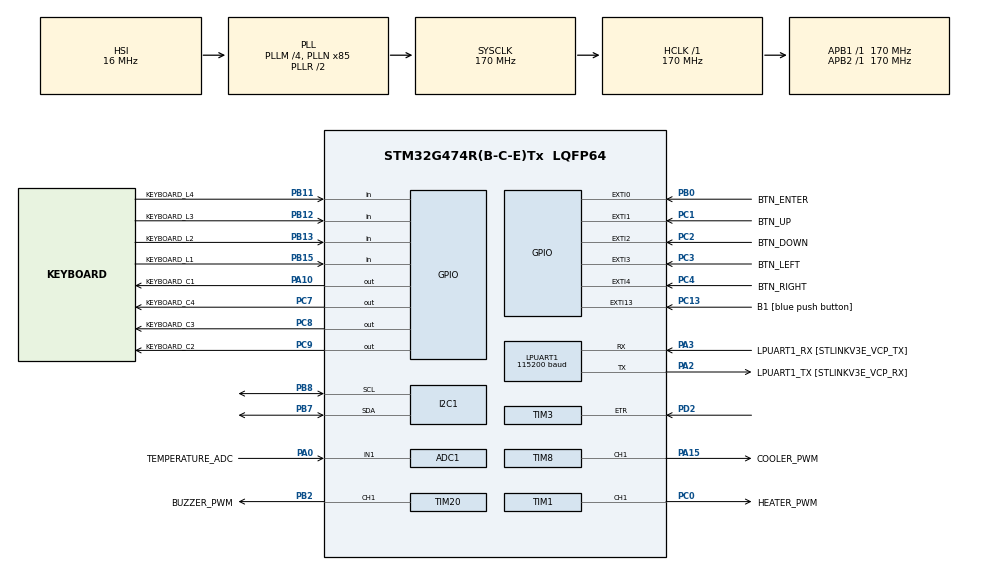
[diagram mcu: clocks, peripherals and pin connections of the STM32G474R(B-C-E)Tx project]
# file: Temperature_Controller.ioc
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ADC1.Channel-0\#ChannelRegularConversion=ADC_CHANNEL_1
ADC1.ClockPrescaler=ADC_CLOCK_ASYNC_DIV64
ADC1.ContinuousConvMode=ENABLE
ADC1.DMAContinuousRequests=ENABLE
ADC1.NbrOfConversionFlag=1
ADC1.OffsetNumber-0\#ChannelRegularConversion=ADC_OFFSET_NONE
ADC1.OversamplingMode=ENABLE
ADC1.Rank-0\#ChannelRegularConversion=1
ADC1.Ratio=ADC_OVERSAMPLING_RATIO_16
ADC1.RightBitShift=ADC_RIGHTBITSHIFT_4
ADC1.SamplingTime-0\#ChannelRegularConversion=ADC_SAMPLETIME_2CYCLES_5
ADC1.master=1
Dma.ADC1.0.Direction=DMA_PERIPH_TO_MEMORY
Dma.ADC1.0.EventEnable=DISABLE
Dma.ADC1.0.Instance=DMA1_Channel1
Dma.ADC1.0.MemDataAlignment=DMA_MDATAALIGN_HALFWORD
Dma.ADC1.0.MemInc=DMA_MINC_ENABLE
Dma.ADC1.0.Mode=DMA_CIRCULAR
Dma.ADC1.0.PeriphDataAlignment=DMA_PDATAALIGN_HALFWORD
Dma.ADC1.0.PeriphInc=DMA_PINC_DISABLE
Dma.ADC1.0.Polarity=HAL_DMAMUX_REQ_GEN_RISING
Dma.ADC1.0.Priority=DMA_PRIORITY_LOW
Dma.ADC1.0.RequestNumber=1
Dma.ADC1.0.SignalID=NONE
Dma.ADC1.0.SyncEnable=DISABLE
Dma.ADC1.0.SyncPolarity=HAL_DMAMUX_SYNC_NO_EVENT
Dma.ADC1.0.SyncRequestNumber=1
Dma.ADC1.0.SyncSignalID=NONE
Dma.Request0=ADC1
I2C1.Timing=0x30A0A7FB
LPUART1.BaudRate=115200
LPUART1.WordLength=UART_WORDLENGTH_8B
Mcu.Family=STM32G4
Mcu.Name=STM32G474R(B-C-E)Tx
Mcu.Package=LQFP64
NVIC.DMA1_Channel1_IRQn=true\:0\:0\:false\:false\:true\:false\:true\:true
NVIC.EXTI0_IRQn=true\:0\:0\:false\:false\:true\:true\:true\:true
NVIC.EXTI15_10_IRQn=true\:0\:0\:false\:false\:true\:true\:true\:true
NVIC.EXTI1_IRQn=true\:0\:0\:false\:false\:true\:true\:true\:true
NVIC.EXTI2_IRQn=true\:0\:0\:false\:false\:true\:true\:true\:true
NVIC.EXTI3_IRQn=true\:0\:0\:false\:false\:true\:true\:true\:true
NVIC.EXTI4_IRQn=true\:0\:0\:false\:false\:true\:true\:true\:true
NVIC.I2C1_EV_IRQn=true\:3\:0\:true\:false\:true\:true\:true\:true
NVIC.LPUART1_IRQn=true\:3\:0\:true\:false\:true\:true\:true\:true
NVIC.PriorityGroup=NVIC_PRIORITYGROUP_4
NVIC.TIM1_TRG_COM_TIM17_IRQn=true\:0\:0\:false\:false\:true\:true\:true\:true
NVIC.TIM1_UP_TIM16_IRQn=true\:3\:0\:true\:false\:true\:true\:true\:true
NVIC.TIM2_IRQn=true\:0\:0\:false\:false\:true\:true\:true\:true
NVIC.TIM4_IRQn=true\:1\:0\:true\:false\:true\:true\:true\:true
NVIC.TIM5_IRQn=true\:5\:0\:true\:false\:true\:true\:true\:true
NVIC.TIM6_DAC_IRQn=true\:3\:0\:true\:false\:true\:true\:true\:true
NVIC.TIM7_DAC_IRQn=true\:3\:0\:true\:false\:true\:true\:true\:true
PA0.GPIO_Label=TEMPERATURE_ADC
PA0.Mode=IN1-Single-Ended
PA0.Signal=ADC1_IN1
PA10.GPIO_Label=KEYBOARD_C1
PA10.Signal=GPIO_Output
PA13.GPIO_Label=T_SWDIO
PA13.Mode=Serial_Wire
PA13.Signal=SYS_JTMS-SWDIO
PA14.GPIO_Label=T_SWCLK
PA14.Mode=Serial_Wire
PA14.Signal=SYS_JTCK-SWCLK
PA15.GPIO_Label=COOLER_PWM
PA15.Signal=S_TIM8_CH1
PA2.GPIO_Label=LPUART1_TX [STLINKV3E_VCP_RX]
PA2.Mode=Asynchronous
PA2.Signal=LPUART1_TX
PA3.GPIO_Label=LPUART1_RX [STLINKV3E_VCP_TX]
PA3.Mode=Asynchronous
PA3.Signal=LPUART1_RX
PB0.GPIO_Label=BTN_ENTER
PB0.Signal=GPXTI0
PB11.GPIO_Label=KEYBOARD_L4
PB11.Signal=GPIO_Input
PB12.GPIO_Label=KEYBOARD_L3
PB12.Signal=GPIO_Input
PB13.GPIO_Label=KEYBOARD_L2
PB13.Signal=GPIO_Input
PB15.GPIO_Label=KEYBOARD_L1
PB15.Signal=GPIO_Input
PB2.GPIO_Label=BUZZER_PWM
PB2.Signal=S_TIM20_CH1
PB3.GPIO_Label=T_SWO
PB3.Signal=SYS_JTDO-SWO
PB7.Mode=I2C
PB7.Signal=I2C1_SDA
PB8-BOOT0.Mode=I2C
PB8-BOOT0.Signal=I2C1_SCL
PC0.GPIO_Label=HEATER_PWM
PC0.Signal=S_TIM1_CH1
PC1.GPIO_Label=BTN_UP
PC1.GPIO_ModeDefaultEXTI=GPIO_MODE_IT_RISING_FALLING
PC1.Signal=GPXTI1
PC13.GPIO_Label=B1 [blue push button]
PC13.Signal=GPXTI13
PC14-OSC32_IN.Mode=LSE-External-Oscillator
PC14-OSC32_IN.Signal=RCC_OSC32_IN
PC15-OSC32_OUT.Mode=LSE-External-Oscillator
PC15-OSC32_OUT.Signal=RCC_OSC32_OUT
PC2.GPIO_Label=BTN_DOWN
PC2.GPIO_ModeDefaultEXTI=GPIO_MODE_IT_RISING_FALLING
PC2.Signal=GPXTI2
PC3.GPIO_Label=BTN_LEFT
PC3.GPIO_ModeDefaultEXTI=GPIO_MODE_IT_RISING_FALLING
PC3.Signal=GPXTI3
PC4.GPIO_Label=BTN_RIGHT
PC4.GPIO_ModeDefaultEXTI=GPIO_MODE_IT_RISING_FALLING
PC4.Signal=GPXTI4
PC7.GPIO_Label=KEYBOARD_C4
PC7.Signal=GPIO_Output
PC8.GPIO_Label=KEYBOARD_C3
PC8.Signal=GPIO_Output
PC9.GPIO_Label=KEYBOARD_C2
PC9.Signal=GPIO_Output
PD2.Signal=S_TIM3_ETR
PF0-OSC_IN.Mode=HSE-External-Oscillator
PF0-OSC_IN.Signal=RCC_OSC_IN
PF1-OSC_OUT.Mode=HSE-External-Oscillator
PF1-OSC_OUT.Signal=RCC_OSC_OUT
ProjectManager.HeapSize=0x200
ProjectManager.StackSize=0x400
ProjectManager.TargetToolchain=STM32CubeIDE
RCC.ADC12Freq_Value=170000000
RCC.ADC345Freq_Value=170000000
RCC.AHBFreq_Value=170000000
RCC.APB1Freq_Value=170000000
RCC.APB1TimFreq_Value=170000000
RCC.APB2Freq_Value=170000000
RCC.APB2TimFreq_Value=170000000
RCC.CortexFreq_Value=170000000
RCC.EXTERNAL_CLOCK_VALUE=12288000
RCC.HCLKFreq_Value=170000000
RCC.HSE_VALUE=24000000
RCC.HSI48_VALUE=48000000
RCC.HSI_VALUE=16000000
RCC.PLLM=RCC_PLLM_DIV4
RCC.PLLN=85
RCC.RTCClockSelection=RCC_RTCCLKSOURCE_LSE
RCC.SYSCLKFreq_VALUE=170000000
RCC.SYSCLKSource=RCC_SYSCLKSOURCE_PLLCLK
RCC.USBFreq_Value=170000000
RCC.VCOOutputFreq_Value=340000000
SH.S_TIM1_CH1.0=TIM1_CH1,PWM Generation1 CH1
SH.S_TIM20_CH1.0=TIM20_CH1,PWM Generation1 CH1
SH.S_TIM3_ETR.0=TIM3_ETR,ClockSourceETR_Mode2
SH.S_TIM8_CH1.0=TIM8_CH1,PWM Generation1 CH1
TIM1.Channel-PWM\ Generation1\ CH1=TIM_CHANNEL_1
TIM1.PeriodNoDither=10000-1
TIM1.Prescaler=17-1
TIM16.PeriodNoDither=10000-1
TIM16.Prescaler=170-1
TIM2.PeriodNoDither=500000
TIM2.Prescaler=170-1
TIM20.Channel-PWM\ Generation1\ CH1=TIM_CHANNEL_1
TIM20.PeriodNoDither=10000-1
TIM20.Prescaler=17-1
TIM4.PeriodNoDither=10000
TIM4.Prescaler=17-1
TIM5.PeriodNoDither=1000000
TIM5.Prescaler=170-1
TIM6.PeriodNoDither=10000-1
TIM6.Prescaler=170-1
TIM7.PeriodNoDither=10000-1
TIM7.Prescaler=170-1
TIM8.Channel-PWM\ Generation1\ CH1=TIM_CHANNEL_1
TIM8.PeriodNoDither=10000
TIM8.Prescaler=17-1
VP_SYS_VS_DBSignals.Mode=DisableDeadBatterySignals
VP_TIM16_VS_ClockSourceINT.Mode=Enable_Timer
VP_TIM1_VS_ClockSourceINT.Mode=Internal
VP_TIM20_VS_ClockSourceINT.Mode=Internal
VP_TIM2_VS_ClockSourceINT.Mode=Internal
VP_TIM4_VS_ClockSourceINT.Mode=Internal
VP_TIM5_VS_ClockSourceINT.Mode=Internal
VP_TIM6_VS_ClockSourceINT.Mode=Enable_Timer
VP_TIM7_VS_ClockSourceINT.Mode=Enable_Timer
VP_TIM8_VS_ClockSourceINT.Mode=Internal
board=NUCLEO-G474RE

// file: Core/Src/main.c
/* USER CODE BEGIN Header */
/**
 ******************************************************************************
 * @file           : main.c
 * @brief          : Main program body
 ******************************************************************************
 * @attention
 *
 * Copyright (c) 2024 STMicroelectronics.
 * All rights reserved.
 *
 * This software is licensed under terms that can be found in the LICENSE file
 * in the root directory of this software component.
 * If no LICENSE file comes with this software, it is provided AS-IS.
 *
 ******************************************************************************
 */
/* USER CODE END Header */
#include "main.h"
#include "adc.h"
#include "dma.h"
#include "i2c.h"
#include "usart.h"
#include "tim.h"
#include "gpio.h"

/* USER CODE BEGIN Includes */
#include "application.h"
#include "matrixKeyboard.h"

/* USER CODE END Includes */

/* USER CODE BEGIN PD */
char first_line[4];

/* USER CODE END PD */

void SystemClock_Config(void);

int main(void)
{

  /* MCU Configuration--------------------------------------------------------*/

  /* Reset of all peripherals, Initializes the Flash interface and the Systick. */
  HAL_Init();

  /* Configure the system clock */
  SystemClock_Config();

  /* Initialize all configured peripherals */
  MX_GPIO_Init();
  MX_DMA_Init();
  MX_LPUART1_UART_Init();
  MX_TIM6_Init();
  MX_TIM7_Init();
  MX_TIM16_Init();
  MX_I2C1_Init();
  MX_TIM1_Init();
  MX_TIM8_Init();
  MX_TIM20_Init();
  MX_TIM5_Init();
  MX_TIM3_Init();
  MX_TIM4_Init();
  MX_ADC1_Init();
  MX_TIM2_Init();

  /* Infinite loop */
    while (1) {

    /* USER CODE BEGIN 3 */
        vApplicationStart();
    }
  /* USER CODE END 3 */
}

void SystemClock_Config(void)
{
  RCC_OscInitTypeDef RCC_OscInitStruct = {0};
  RCC_ClkInitTypeDef RCC_ClkInitStruct = {0};

  /** Configure the main internal regulator output voltage
  */
  HAL_PWREx_ControlVoltageScaling(PWR_REGULATOR_VOLTAGE_SCALE1_BOOST);

  /** Initializes the RCC Oscillators according to the specified parameters
  * in the RCC_OscInitTypeDef structure.
  */
  RCC_OscInitStruct.OscillatorType = RCC_OSCILLATORTYPE_HSI;
  RCC_OscInitStruct.HSIState = RCC_HSI_ON;
  RCC_OscInitStruct.HSICalibrationValue = RCC_HSICALIBRATION_DEFAULT;
  RCC_OscInitStruct.PLL.PLLState = RCC_PLL_ON;
  RCC_OscInitStruct.PLL.PLLSource = RCC_PLLSOURCE_HSI;
  RCC_OscInitStruct.PLL.PLLM = RCC_PLLM_DIV4;
  RCC_OscInitStruct.PLL.PLLN = 85;
  RCC_OscInitStruct.PLL.PLLP = RCC_PLLP_DIV2;
  RCC_OscInitStruct.PLL.PLLQ = RCC_PLLQ_DIV2;
  RCC_OscInitStruct.PLL.PLLR = RCC_PLLR_DIV2;
  if (HAL_RCC_OscConfig(&RCC_OscInitStruct) != HAL_OK)
  {
    Error_Handler();
  }

  /** Initializes the CPU, AHB and APB buses clocks
  */
  RCC_ClkInitStruct.ClockType = RCC_CLOCKTYPE_HCLK|RCC_CLOCKTYPE_SYSCLK
                              |RCC_CLOCKTYPE_PCLK1|RCC_CLOCKTYPE_PCLK2;
  RCC_ClkInitStruct.SYSCLKSource = RCC_SYSCLKSOURCE_PLLCLK;
  RCC_ClkInitStruct.AHBCLKDivider = RCC_SYSCLK_DIV1;
  RCC_ClkInitStruct.APB1CLKDivider = RCC_HCLK_DIV1;
  RCC_ClkInitStruct.APB2CLKDivider = RCC_HCLK_DIV1;

  if (HAL_RCC_ClockConfig(&RCC_ClkInitStruct, FLASH_LATENCY_4) != HAL_OK)
  {
    Error_Handler();
  }
}

void Error_Handler(void)
{
    __disable_irq();
    while (1) {
    }
}
